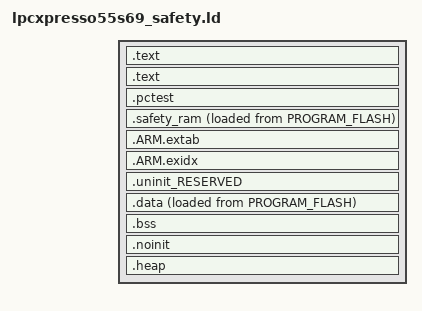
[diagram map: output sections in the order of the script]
/*
 * Copyright 2019 NXP.
 * All rights reserved.
 *
 * SPDX-License-Identifier: BSD-3-Clause
 */

/*     
 *     Processors:          LPC55S69JBD100_cm33_core0
 *                          LPC55S69JBD64_cm33_core0
 *                          LPC55S69JEV98_cm33_core0
 */

INCLUDE "lpcxpresso55s69_safety_library.ld"
INCLUDE "lpcxpresso55s69_safety_memory.ld"

ENTRY(ResetISR)

SECTIONS
{
    /* MAIN TEXT SECTION */
    .text : ALIGN(4)
    {
    	/**** IVT ****/
        FILL(0xff)
        __vectors_start__ = ABSOLUTE(.) ;
        KEEP(*(.isr_vector))
        /**** IVT ****/    	
    	
        /* Global Section Table */
        . = ALIGN(4) ;
        __section_table_start = .;
        __data_section_table = .;
        LONG(LOADADDR(.data));
        LONG(    ADDR(.data));
        LONG(  SIZEOF(.data));
        __data_section_table_end = .;
        __safety_ram_section_table = .;
        LONG(LOADADDR(.safety_ram));
        LONG(    ADDR(.safety_ram));
        LONG(  SIZEOF(.safety_ram));
        __safety_ram_section_table_end = .;
        __bss_section_table = .;
        LONG(    ADDR(.bss));
        LONG(  SIZEOF(.bss));
        __bss_section_table_end = .;
        __section_table_end = . ;
        /* End of Global Section Table */

        *(.after_vectors*)

    } > PROGRAM_FLASH

    .text : ALIGN(4)
    {
       *(.text*)
       KEEP(*(.rodata .rodata.* .constdata .constdata.*))
       . = ALIGN(4);

       /**** CRC ****/
       . = ALIGN(4);  
       FILL(0xff)     
       . = 0xFFF0;     
       /**** CRC ****/

    } > PROGRAM_FLASH

    .pctest : 
    {
    . = ALIGN(4);
    *iec60730b_cm33_pc_object.o
    . = ALIGN(4);
    } > PCTEST_region

    .safety_ram : ALIGN(4)    
    {
    _safety_ram = .;
    *(.safety_ram*)
    . = ALIGN(4);
    _end_safety_ram = .;
    } > SRAM AT>PROGRAM_FLASH 

    /*
     * for exception handling/unwind - some Newlib functions (in common
     * with C++ and STDC++) use this. 
     */
    .ARM.extab : ALIGN(4) 
    {
        *(.ARM.extab* .gnu.linkonce.armextab.*)
    } > PROGRAM_FLASH

    __exidx_start = .;

    .ARM.exidx : ALIGN(4)
    {
        *(.ARM.exidx* .gnu.linkonce.armexidx.*)
    } > PROGRAM_FLASH
    __exidx_end = .;
 
    _etext = .;
    
    /* MAIN DATA SECTION */
    .uninit_RESERVED : ALIGN(4)
    {
        KEEP(*(.bss.$RESERVED*))
        . = ALIGN(4) ;
        _end_uninit_RESERVED = .;
    } > SRAM

    /* Main DATA section (SRAM) */
    .data : ALIGN(4)
    {
       FILL(0xff)
       _data = . ;
       *(vtable)
       *(.ramfunc*)
       *(.data*)
       . = ALIGN(4) ;
       _edata = . ;  
    } > SRAM AT>PROGRAM_FLASH

    /* MAIN BSS SECTION */
    .bss : ALIGN(4)
    {
        _bss = .;
        *(.bss*)
        *(COMMON)
        . = ALIGN(4) ;
        _ebss = .;
        PROVIDE(end = .);
    } > SRAM

    /* DEFAULT NOINIT SECTION */
    .noinit (NOLOAD): ALIGN(4)
    {
        _noinit = .;
        *(.noinit*) 
         . = ALIGN(4) ;
        _end_noinit = .;
    } > SRAM

    /* Reserve and place Heap within memory map */
    _HeapSize = 0x1000;
    .heap :  ALIGN(4)
    {
        _pvHeapStart = .;
        . += _HeapSize;
        . = ALIGN(4);
        _pvHeapLimit = .;
    } > SRAM

    /* ## Create checksum value (used in startup) ## */
    PROVIDE(__valid_user_code_checksum = 0 - 
                                         (stackTop 
                                         + (ResetISR + 1) 
                                         + (NMI_Handler + 1) 
                                         + (HardFault_Handler + 1) 
                                         + (( DEFINED(MemManage_Handler) ? MemManage_Handler : 0 ) + 1)   /* MemManage_Handler may not be defined */
                                         + (( DEFINED(BusFault_Handler) ? BusFault_Handler : 0 ) + 1)     /* BusFault_Handler may not be defined */
                                         + (( DEFINED(UsageFault_Handler) ? UsageFault_Handler : 0 ) + 1) /* UsageFault_Handler may not be defined */
                                         ) );

    /* Provide basic symbols giving location and size of main text
     * block, including initial values of RW data sections. Note that
     * these will need extending to give a complete picture with
     * complex images (e.g multiple Flash banks).
     */
    _image_start = LOADADDR(.text);
    _image_end = LOADADDR(.data) + SIZEOF(.data);
    _image_size = _image_end - _image_start;
}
